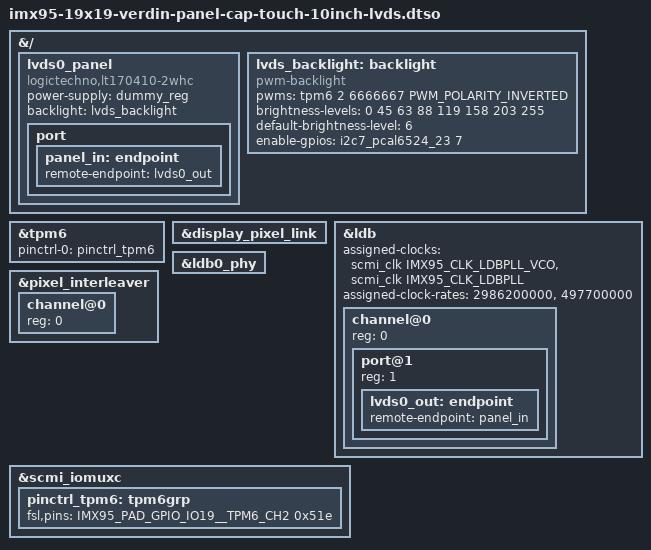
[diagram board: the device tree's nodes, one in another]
// SPDX-License-Identifier: (GPL-2.0+ OR MIT)
/*
 * Copyright 2024 NXP
 */
/dts-v1/;
/plugin/;

#include <dt-bindings/clock/fsl,imx95-clock.h>
#include <dt-bindings/gpio/gpio.h>
#include <dt-bindings/pwm/pwm.h>
#include "imx95-pinfunc.h"

&{/} {
	lvds0_panel {
		compatible = "logictechno,lt170410-2whc";
		power-supply = <&dummy_reg>;
		backlight = <&lvds_backlight>;

		port {
			panel_in: endpoint {
				remote-endpoint = <&lvds0_out>;
			};
		};
	};

	lvds_backlight: backlight {
		compatible = "pwm-backlight";
		pwms = <&tpm6 2 6666667 PWM_POLARITY_INVERTED>;
		brightness-levels = <0 45 63 88 119 158 203 255>;
		default-brightness-level = <6>;
		enable-gpios = <&i2c7_pcal6524_23 7 GPIO_ACTIVE_HIGH>;
	};
};

&tpm6 {
	pinctrl-names = "default";
	pinctrl-0 = <&pinctrl_tpm6>;
	status = "okay";
};

&display_pixel_link {
	status = "okay";
};

&ldb {
	#address-cells = <1>;
	#size-cells = <0>;
	assigned-clocks = <&scmi_clk IMX95_CLK_LDBPLL_VCO>,
			  <&scmi_clk IMX95_CLK_LDBPLL>;
	assigned-clock-rates = <2986200000>, <497700000>;
	status = "okay";

	channel@0 {
		#address-cells = <1>;
		#size-cells = <0>;
		reg = <0>;
		status = "okay";

		port@1 {
			reg = <1>;

			lvds0_out: endpoint {
				remote-endpoint = <&panel_in>;
			};
		};
	};
};

&ldb0_phy {
	status = "okay";
};

&pixel_interleaver {
	#address-cells = <1>;
	#size-cells = <0>;
	status = "okay";

	channel@0 {
		reg = <0>;
		status = "okay";
	};
};

&scmi_iomuxc {
	pinctrl_tpm6: tpm6grp {
		fsl,pins = <
			IMX95_PAD_GPIO_IO19__TPM6_CH2	0x51e
		>;
	};
};
